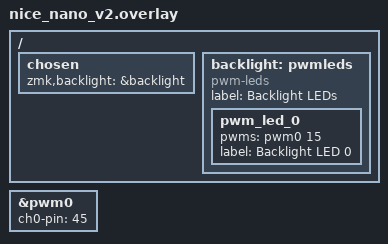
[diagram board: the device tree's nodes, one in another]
&pwm0 {
    status = "okay";
    ch0-pin = <45>;
    /* ch0-inverted; */
};

/ {
    chosen {
        zmk,backlight = &backlight;
    };
    backlight: pwmleds {
        compatible = "pwm-leds";
        label = "Backlight LEDs";
        pwm_led_0 {
            pwms = <&pwm0 15>;
            label = "Backlight LED 0";
        };
    };
};
